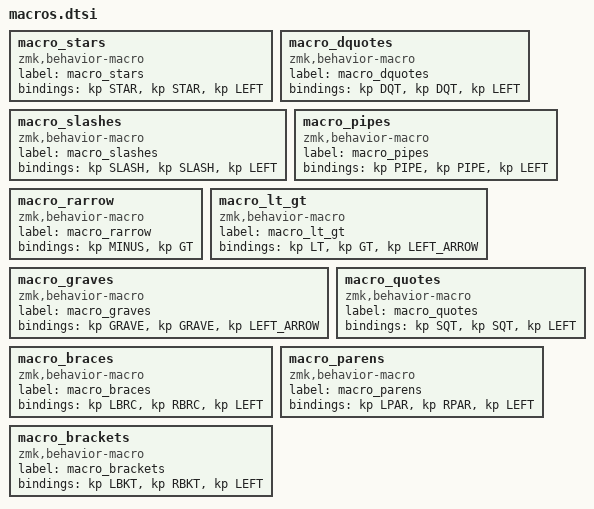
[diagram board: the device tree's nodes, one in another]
macro_stars: macro_stars{
compatible = "zmk,behavior-macro";
label = "macro_stars";
#binding-cells = <0>;
bindings = <&kp STAR>, <&kp STAR>, <&kp LEFT>;
};
macro_dquotes: macro_dquotes{
compatible = "zmk,behavior-macro";
label = "macro_dquotes";
#binding-cells = <0>;
bindings = <&kp DQT>, <&kp DQT>, <&kp LEFT>;
};
macro_slashes: macro_slashes{
compatible = "zmk,behavior-macro";
label = "macro_slashes";
#binding-cells = <0>;
bindings = <&kp SLASH>, <&kp SLASH>, <&kp LEFT>;
};
macro_pipes: macro_pipes{
compatible = "zmk,behavior-macro";
label = "macro_pipes";
#binding-cells = <0>;
bindings = <&kp PIPE>, <&kp PIPE>, <&kp LEFT>;
};
macro_rarrow: macro_rarrow{
compatible = "zmk,behavior-macro";
label = "macro_rarrow";
#binding-cells = <0>;
bindings = <&kp MINUS>, <&kp GT>;
};
macro_lt_gt: macro_lt_gt{
compatible = "zmk,behavior-macro";
label = "macro_lt_gt";
#binding-cells = <0>;
bindings = <&kp LT>, <&kp GT>, <&kp LEFT_ARROW>;
};
macro_graves: macro_graves{
compatible = "zmk,behavior-macro";
label = "macro_graves";
#binding-cells = <0>;
bindings = <&kp GRAVE>, <&kp GRAVE>, <&kp LEFT_ARROW>;
};
macro_quotes: macro_quotes{
compatible = "zmk,behavior-macro";
label = "macro_quotes";
#binding-cells = <0>;
bindings = <&kp SQT>, <&kp SQT>, <&kp LEFT>;
};
macro_braces: macro_braces{
compatible = "zmk,behavior-macro";
label = "macro_braces";
#binding-cells = <0>;
bindings = <&kp LBRC>, <&kp RBRC>, <&kp LEFT>;
};
macro_parens: macro_parens{
compatible = "zmk,behavior-macro";
label = "macro_parens";
#binding-cells = <0>;
bindings = <&kp LPAR>, <&kp RPAR>, <&kp LEFT>;
};
macro_brackets: macro_brackets{
compatible = "zmk,behavior-macro";
label = "macro_brackets";
#binding-cells = <0>;
bindings = <&kp LBKT>, <&kp RBKT>, <&kp LEFT>;
};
